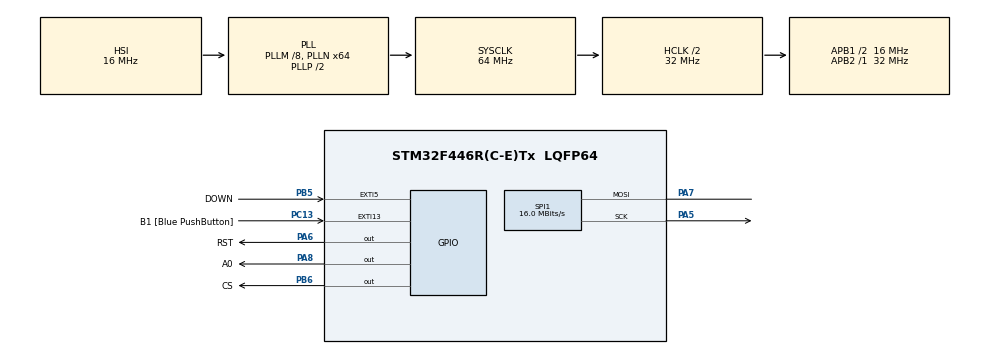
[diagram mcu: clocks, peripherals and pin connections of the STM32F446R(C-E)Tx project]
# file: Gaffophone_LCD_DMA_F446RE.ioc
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Mcu.Family=STM32F4
Mcu.Name=STM32F446R(C-E)Tx
Mcu.Package=LQFP64
NVIC.EXTI9_5_IRQn=true\:0\:0\:false\:false\:true\:true\:true\:true
NVIC.FPU_IRQn=true\:0\:0\:false\:false\:true\:true\:false\:true
NVIC.PriorityGroup=NVIC_PRIORITYGROUP_0
PA13.GPIO_Label=TMS
PA13.Mode=Serial_Wire
PA13.Signal=SYS_JTMS-SWDIO
PA14.GPIO_Label=TCK
PA14.Mode=Serial_Wire
PA14.Signal=SYS_JTCK-SWCLK
PA2.GPIO_Label=USART_TX
PA2.Signal=USART2_TX
PA3.GPIO_Label=USART_RX
PA3.Signal=USART2_RX
PA5.Mode=Simplex_Bidirectional_Master
PA5.Signal=SPI1_SCK
PA6.GPIO_Label=RST
PA6.Signal=GPIO_Output
PA7.Mode=Simplex_Bidirectional_Master
PA7.Signal=SPI1_MOSI
PA8.GPIO_Label=A0
PA8.Signal=GPIO_Output
PB3.GPIO_Label=SWO
PB3.Signal=SYS_JTDO-SWO
PB5.GPIO_Label=DOWN
PB5.Signal=GPXTI5
PB6.GPIO_Label=CS
PB6.Signal=GPIO_Output
PC13.GPIO_Label=B1 [Blue PushButton]
PC13.GPIO_ModeDefaultEXTI=GPIO_MODE_IT_FALLING
PC13.Signal=GPXTI13
PC14-OSC32_IN.Mode=LSE-External-Oscillator
PC14-OSC32_IN.Signal=RCC_OSC32_IN
PC15-OSC32_OUT.Mode=LSE-External-Oscillator
PC15-OSC32_OUT.Signal=RCC_OSC32_OUT
PH0-OSC_IN.Mode=HSE-External-Oscillator
PH0-OSC_IN.Signal=RCC_OSC_IN
PH1-OSC_OUT.Mode=HSE-External-Oscillator
PH1-OSC_OUT.Signal=RCC_OSC_OUT
ProjectManager.HeapSize=0x200
ProjectManager.StackSize=0x400
ProjectManager.TargetToolchain=STM32CubeIDE
RCC.48MHZClocksFreq_Value=84000000
RCC.AHBCLKDivider=RCC_SYSCLK_DIV2
RCC.AHBFreq_Value=32000000
RCC.APB1CLKDivider=RCC_HCLK_DIV2
RCC.APB1Freq_Value=16000000
RCC.APB1TimFreq_Value=32000000
RCC.APB2Freq_Value=32000000
RCC.APB2TimFreq_Value=32000000
RCC.CortexFreq_Value=32000000
RCC.FLatency-AdvancedSettings=FLASH_LATENCY_1
RCC.HCLKFreq_Value=32000000
RCC.HSE_VALUE=8000000
RCC.HSI_VALUE=16000000
RCC.PLLM=8
RCC.PLLN=64
RCC.SYSCLKFreq_VALUE=64000000
RCC.SYSCLKSource=RCC_SYSCLKSOURCE_PLLCLK
RCC.USBFreq_Value=64000000
RCC.VCOOutputFreq_Value=128000000
SPI1.CalculateBaudRate=16.0 MBits/s
SPI1.Direction=SPI_DIRECTION_1LINE
SPI1.Mode=SPI_MODE_MASTER
SPI1.VirtualType=VM_MASTER
board=NUCLEO-F446RE

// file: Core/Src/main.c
/* USER CODE BEGIN Header */
/**
  ******************************************************************************
  * @file           : main.c
  * @brief          : Main program body
  ******************************************************************************
  * @attention
  *
  * Copyright (c) 2023 STMicroelectronics.
  * All rights reserved.
  *
  * This software is licensed under terms that can be found in the LICENSE file
  * in the root directory of this software component.
  * If no LICENSE file comes with this software, it is provided AS-IS.
  *
  ******************************************************************************
  */
/* USER CODE END Header */
#include "main.h"

/* USER CODE BEGIN Includes */
#include "gaffophone_app.h"
/* USER CODE END Includes */

SPI_HandleTypeDef hspi1;

void SystemClock_Config(void);
static void MX_GPIO_Init(void);
static void MX_SPI1_Init(void);
/* USER CODE BEGIN PFP */
uint8_t flag_bp_down = 0;
/* USER CODE END PFP */

int main(void)
{

  /* MCU Configuration--------------------------------------------------------*/

  /* Reset of all peripherals, Initializes the Flash interface and the Systick. */
  HAL_Init();

  /* Configure the system clock */
  SystemClock_Config();

  /* Initialize all configured peripherals */
  MX_GPIO_Init();
  MX_SPI1_Init();

  /* Infinite loop */
  /* USER CODE BEGIN WHILE */
  while (1)
  {
	  HAL_Delay(100);
	  gaffophone_app_fsm();
    /* USER CODE END WHILE */

  }
}

void SystemClock_Config(void)
{
  RCC_OscInitTypeDef RCC_OscInitStruct = {0};
  RCC_ClkInitTypeDef RCC_ClkInitStruct = {0};

  /** Configure the main internal regulator output voltage
  */
  __HAL_RCC_PWR_CLK_ENABLE();
  __HAL_PWR_VOLTAGESCALING_CONFIG(PWR_REGULATOR_VOLTAGE_SCALE3);

  /** Initializes the RCC Oscillators according to the specified parameters
  * in the RCC_OscInitTypeDef structure.
  */
  RCC_OscInitStruct.OscillatorType = RCC_OSCILLATORTYPE_HSI;
  RCC_OscInitStruct.HSIState = RCC_HSI_ON;
  RCC_OscInitStruct.HSICalibrationValue = RCC_HSICALIBRATION_DEFAULT;
  RCC_OscInitStruct.PLL.PLLState = RCC_PLL_ON;
  RCC_OscInitStruct.PLL.PLLSource = RCC_PLLSOURCE_HSI;
  RCC_OscInitStruct.PLL.PLLM = 8;
  RCC_OscInitStruct.PLL.PLLN = 64;
  RCC_OscInitStruct.PLL.PLLP = RCC_PLLP_DIV2;
  RCC_OscInitStruct.PLL.PLLQ = 2;
  RCC_OscInitStruct.PLL.PLLR = 2;
  if (HAL_RCC_OscConfig(&RCC_OscInitStruct) != HAL_OK)
  {
    Error_Handler();
  }

  /** Initializes the CPU, AHB and APB buses clocks
  */
  RCC_ClkInitStruct.ClockType = RCC_CLOCKTYPE_HCLK|RCC_CLOCKTYPE_SYSCLK
                              |RCC_CLOCKTYPE_PCLK1|RCC_CLOCKTYPE_PCLK2;
  RCC_ClkInitStruct.SYSCLKSource = RCC_SYSCLKSOURCE_PLLCLK;
  RCC_ClkInitStruct.AHBCLKDivider = RCC_SYSCLK_DIV2;
  RCC_ClkInitStruct.APB1CLKDivider = RCC_HCLK_DIV2;
  RCC_ClkInitStruct.APB2CLKDivider = RCC_HCLK_DIV1;

  if (HAL_RCC_ClockConfig(&RCC_ClkInitStruct, FLASH_LATENCY_1) != HAL_OK)
  {
    Error_Handler();
  }
}

static void MX_SPI1_Init(void)
{

  /* SPI1 parameter configuration*/
  hspi1.Instance = SPI1;
  hspi1.Init.Mode = SPI_MODE_MASTER;
  hspi1.Init.Direction = SPI_DIRECTION_1LINE;
  hspi1.Init.DataSize = SPI_DATASIZE_8BIT;
  hspi1.Init.CLKPolarity = SPI_POLARITY_LOW;
  hspi1.Init.CLKPhase = SPI_PHASE_1EDGE;
  hspi1.Init.NSS = SPI_NSS_SOFT;
  hspi1.Init.BaudRatePrescaler = SPI_BAUDRATEPRESCALER_2;
  hspi1.Init.FirstBit = SPI_FIRSTBIT_MSB;
  hspi1.Init.TIMode = SPI_TIMODE_DISABLE;
  hspi1.Init.CRCCalculation = SPI_CRCCALCULATION_DISABLE;
  hspi1.Init.CRCPolynomial = 10;
  if (HAL_SPI_Init(&hspi1) != HAL_OK)
  {
    Error_Handler();
  }

}

static void MX_GPIO_Init(void)
{
  GPIO_InitTypeDef GPIO_InitStruct = {0};

  /* GPIO Ports Clock Enable */
  __HAL_RCC_GPIOC_CLK_ENABLE();
  __HAL_RCC_GPIOH_CLK_ENABLE();
  __HAL_RCC_GPIOA_CLK_ENABLE();
  __HAL_RCC_GPIOB_CLK_ENABLE();

  /*Configure GPIO pin Output Level */
  HAL_GPIO_WritePin(GPIOA, RST_Pin|A0_Pin, GPIO_PIN_RESET);

  /*Configure GPIO pin Output Level */
  HAL_GPIO_WritePin(CS_GPIO_Port, CS_Pin, GPIO_PIN_RESET);

  /*Configure GPIO pin : B1_Pin */
  GPIO_InitStruct.Pin = B1_Pin;
  GPIO_InitStruct.Mode = GPIO_MODE_IT_FALLING;
  GPIO_InitStruct.Pull = GPIO_NOPULL;
  HAL_GPIO_Init(B1_GPIO_Port, &GPIO_InitStruct);

  /*Configure GPIO pins : USART_TX_Pin USART_RX_Pin */
  GPIO_InitStruct.Pin = USART_TX_Pin|USART_RX_Pin;
  GPIO_InitStruct.Mode = GPIO_MODE_AF_PP;
  GPIO_InitStruct.Pull = GPIO_NOPULL;
  GPIO_InitStruct.Speed = GPIO_SPEED_FREQ_VERY_HIGH;
  GPIO_InitStruct.Alternate = GPIO_AF7_USART2;
  HAL_GPIO_Init(GPIOA, &GPIO_InitStruct);

  /*Configure GPIO pins : RST_Pin A0_Pin */
  GPIO_InitStruct.Pin = RST_Pin|A0_Pin;
  GPIO_InitStruct.Mode = GPIO_MODE_OUTPUT_PP;
  GPIO_InitStruct.Pull = GPIO_NOPULL;
  GPIO_InitStruct.Speed = GPIO_SPEED_FREQ_LOW;
  HAL_GPIO_Init(GPIOA, &GPIO_InitStruct);

  /*Configure GPIO pin : DOWN_Pin */
  GPIO_InitStruct.Pin = DOWN_Pin;
  GPIO_InitStruct.Mode = GPIO_MODE_IT_RISING;
  GPIO_InitStruct.Pull = GPIO_NOPULL;
  HAL_GPIO_Init(DOWN_GPIO_Port, &GPIO_InitStruct);

  /*Configure GPIO pin : CS_Pin */
  GPIO_InitStruct.Pin = CS_Pin;
  GPIO_InitStruct.Mode = GPIO_MODE_OUTPUT_PP;
  GPIO_InitStruct.Pull = GPIO_NOPULL;
  GPIO_InitStruct.Speed = GPIO_SPEED_FREQ_LOW;
  HAL_GPIO_Init(CS_GPIO_Port, &GPIO_InitStruct);

  /* EXTI interrupt init*/
  HAL_NVIC_SetPriority(EXTI9_5_IRQn, 0, 0);
  HAL_NVIC_EnableIRQ(EXTI9_5_IRQn);

}

/* USER CODE BEGIN 4 */
void HAL_GPIO_EXTI_Callback(uint16_t GPIO_Pin)
{
	flag_bp_down = 1;
}
/* USER CODE END 4 */

void Error_Handler(void)
{
  __disable_irq();
  while (1)
  {
  }
}
